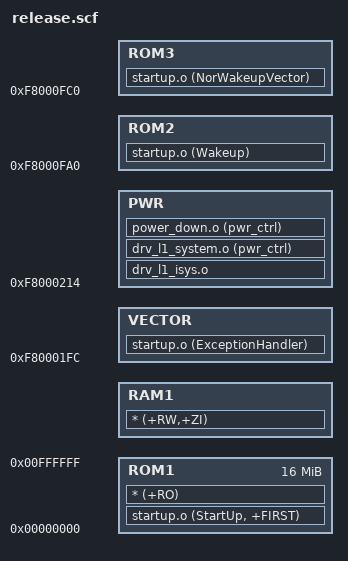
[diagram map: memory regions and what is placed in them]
ROM_LOAD 0x00000000 0x1000000
{
    ROM1 0x00000000 0x1000000
    {
        startup.o (StartUp, +FIRST)
    	* (+RO)
    }

    RAM1 +0
    {
        * (+RW,+ZI)
    }

	VECTOR 0xF80001FC
	{
		startup.o (ExceptionHandler)
	}
	
	PWR 0xF8000214
	{
		drv_l1_isys.o
		drv_l1_system.o (pwr_ctrl)
		power_down.o (pwr_ctrl)
;		system_dynamicallyclock.o (pwr_ctrl)
	}
	
    ROM2 0xF8000FA0
	{
		startup.o (Wakeup)
	}

	ROM3 0xF8000FC0
	{
		startup.o (NorWakeupVector)
	}
}
